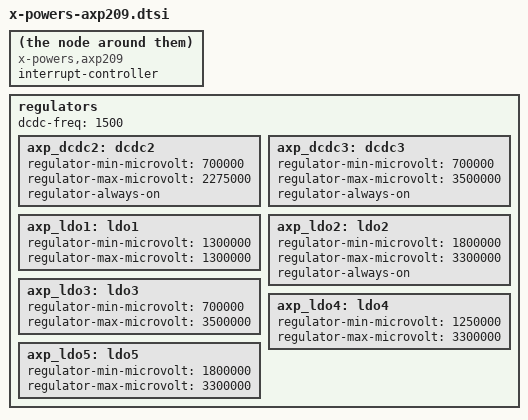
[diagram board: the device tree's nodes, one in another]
/*
 * x-powers,axp209 common code to be include from inside the axp209 node
 *
 * Copyright 2014 - Carlo Caione <carlo@caione.org>
 *
 * The code contained herein is licensed under the GNU General Public
 * License. You may obtain a copy of the GNU General Public License
 * Version 2 or later at the following locations:
 *
 * http://www.opensource.org/licenses/gpl-license.html
 * http://www.gnu.org/copyleft/gpl.html
 */

	compatible = "x-powers,axp209";
	interrupt-controller;
	#interrupt-cells = <1>;

	regulators {
		dcdc-freq = <1500>;

		axp_dcdc2: dcdc2 {
			regulator-min-microvolt = <700000>;
			regulator-max-microvolt = <2275000>;
			regulator-always-on;
		};

		axp_dcdc3: dcdc3 {
			regulator-min-microvolt = <700000>;
			regulator-max-microvolt = <3500000>;
			regulator-always-on;
		};

		axp_ldo1: ldo1 {
			regulator-min-microvolt = <1300000>;
			regulator-max-microvolt = <1300000>;
		};

		axp_ldo2: ldo2 {
			regulator-min-microvolt = <1800000>;
			regulator-max-microvolt = <3300000>;
			regulator-always-on;
		};

		axp_ldo3: ldo3 {
			regulator-min-microvolt = <700000>;
			regulator-max-microvolt = <3500000>;
		};

		axp_ldo4: ldo4 {
			regulator-min-microvolt = <1250000>;
			regulator-max-microvolt = <3300000>;
		};

		axp_ldo5: ldo5 {
			regulator-min-microvolt = <1800000>;
			regulator-max-microvolt = <3300000>;
		};
	};
